# STM32MP21_CA35 register map
File version: 0.4
CPU: CM33 r0p1, little endian, MPU, FPU, vendor SysTick, 8 interrupt priority bits
Registers are 32-bit, read-write, reset 0x0 unless marked. A register's access mark holds for its fields unless they carry their own. Offsets are from the block's base; [hi:lo] are bit positions; lines under a group give offsets from that group; {n}, {i} and the like mark numbered series.

## I3C1 (part 2 of 2) — I3C register block
Base 0x40190000
Same registers: I3C2 0x401A0000, I3C3 0x46080000, I3C1_S 0x50190000, I3C2_S 0x501A0000, I3C3_S 0x56080000
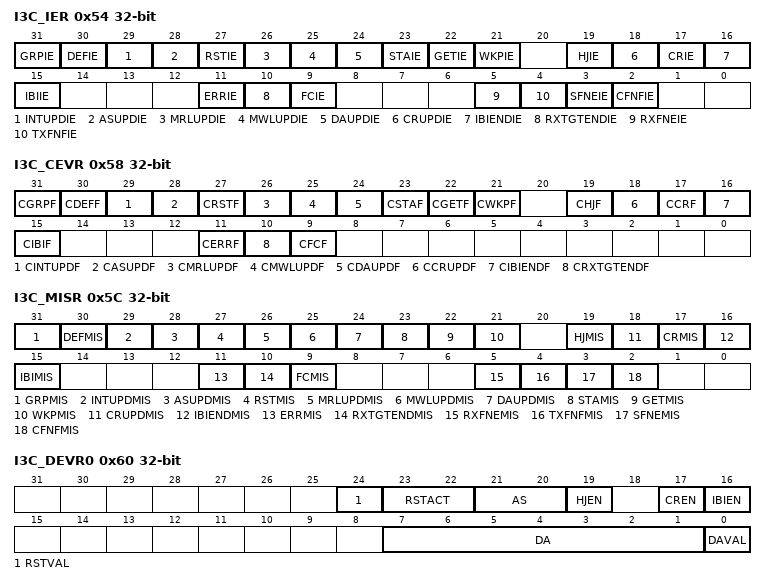
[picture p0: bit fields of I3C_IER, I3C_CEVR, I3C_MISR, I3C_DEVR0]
0x54 I3C_IER ro — I3C interrupt enable register
  [all] fields
    0=interrupt disabled; 1=interrupt enabled
  [31] GRPIE — DEFGRPA CCC interrupt enable (when the I3C acts as target)
  [30] DEFIE — DEFTGTS CCC interrupt enable (when the I3C acts as target)
  [29] INTUPDIE — ENEC/DISEC CCC interrupt enable (when the I3C acts as target)
  [28] ASUPDIE — ENTASx CCC interrupt enable (when the I3C acts as target)
  [27] RSTIE — reset pattern interrupt enable (when the I3C acts as target)
  [26] MRLUPDIE — SETMRL CCC interrupt enable (when the I3C acts as target)
  [25] MWLUPDIE — SETMWL CCC interrupt enable (when the I3C acts as target)
  [24] DAUPDIE — ENTDAA/RSTDAA/SETNEWDA CCC interrupt enable (when the I3C acts as target)
  [23] STAIE — format 1 GETSTATUS CCC interrupt enable (when the I3C acts as target)
  [22] GETIE — GETxxx CCC interrupt enable (except GETSTATUS of format 1) (when the I3C acts as target)
  [21] WKPIE — Wake-up interrupt enable (when the I3C acts as target)
  [19] HJIE — Hot-join interrupt enable (when the I3C acts as controller)
  [18] CRUPDIE — Controller-role update interrupt enable (when the I3C acts as target)
  [17] CRIE — Controller-role request interrupt enable (when the I3C acts as controller)
  [16] IBIENDIE — IBI end interrupt enable (when the I3C acts as target)
  [15] IBIIE — IBI request interrupt enable (when the I3C acts as controller)
  [11] ERRIE — error interrupt enable (whatever the I3C acts as controller/target)
  [10] RXTGTENDIE — target-initiated read end interrupt enable (when the I3C acts as controller)
  [9] FCIE — frame complete interrupt enable (whatever the I3C acts as controller/target)
  [5] RXFNEIE — RX-FIFO not empty interrupt enable (whatever the I3C acts as controller/target)
  [4] TXFNFIE — TX-FIFO not full interrupt enable (whatever the I3C acts as controller/target)
  [3] SFNEIE — S-FIFO not empty interrupt enable when the I3C acts as controller
  [2] CFNFIE — C-FIFO not full interrupt enable when the I3C acts as controller
0x58 I3C_CEVR wo — I3C clear event register
  [31] CGRPF — Clear DEFGRPA CCC flag (when the I3C acts as target)
    0=no effect; 1=clear GRPF
  [30] CDEFF — Clear DEFTGTS CCC flag (when the I3C acts as target)
    0=no effect; 1=clear DEFF
  [29] CINTUPDF — Clear ENEC/DISEC CCC flag (when the I3C acts as target)
    0=no effect; 1=clear CINTUPDF
  [28] CASUPDF — Clear ENTASx CCC flag (when the I3C acts as target)
    0=no effect; 1=clear ASUPDF
  [27] CRSTF — Clear reset pattern flag (when the I3C acts as target)
    0=no effect; 1=clear RSTF
  [26] CMRLUPDF — Clear SETMRL CCC flag (when the I3C acts as target)
    0=no effect; 1=clear MRLUPDF
  [25] CMWLUPDF — Clear SETMWL CCC flag (when the I3C acts as target)
    0=no effect; 1=clear MWLUPDF
  [24] CDAUPDF — Clear ENTDAA/RSTDAA/SETNEWDA CCC flag (when the I3C acts as target)
    0=no effect; 1=clear DAUPDF
  [23] CSTAF — Clear format 1 GETSTATUS CCC flag (when the I3C acts as target)
    0=no effect; 1=clear STAF
  [22] CGETF — Clear GETxxx CCC flag (except GETSTATUS of format 1) (when the I3C acts as target)
    0=no effect; 1=clear GETF
  [21] CWKPF — Clear wake-up flag (when the I3C acts as target)
    0=no effect; 1=clear WKPF
  [19] CHJF — Clear hot-join flag (when the I3C acts as controller)
    0=no effect; 1=clear HJF
  [18] CCRUPDF — Clear controller-role update flag (when the I3C acts as target)
    0=no effect; 1=clear CRUPDF
  [17] CCRF — Clear controller-role request flag (when the I3C acts as controller)
    0=no effect; 1=clear CRF
  [16] CIBIENDF — Clear IBI end flag (when the I3C acts as target)
    0=no effect; 1=clear IBIENDF
  [15] CIBIF — Clear IBI request flag (when the I3C acts as controller)
    0=no effect; 1=clear IBIF
  [11] CERRF — Clear error flag (whatever the I3C acts as controller/target)
    0=no effect; 1=clear ERRF
  [10] CRXTGTENDF — Clear target-initiated read end flag (when the I3C acts as controller)
    0=no effect; 1=clear RXTGTENDF
  [9] CFCF — Clear frame complete flag (whatever the I3C acts as controller/target)
    0=no effect; 1=clear FCF
0x5C I3C_MISR ro — I3C masked interrupt status register
  [31] GRPMIS — DEFGRPA CCC masked interrupt status (when the I3C acts as target)
  [30] DEFMIS — DEFTGTS CCC masked interrupt status (when the I3C acts as target)
  [29] INTUPDMIS — ENEC/DISEC CCC masked interrupt status (when the I3C acts as target)
  [28] ASUPDMIS — ENTASx CCC masked interrupt status (when the I3C acts as target)
  [27] RSTMIS — reset pattern masked interrupt status (when the I3C acts as target)
  [26] MRLUPDMIS — SETMRL CCC masked interrupt status (when the I3C acts as target)
  [25] MWLUPDMIS — SETMWL CCC masked interrupt status (when the I3C acts as target)
  [24] DAUPDMIS — ENTDAA/RSTDAA/SETNEWDA CCC masked interrupt status (when the I3C acts as target)
  [23] STAMIS — format 1 GETSTATUS CCC masked interrupt status (when the I3C acts as target)
  [22] GETMIS — GETxxx CCC masked interrupt status, except GETSTATUS of format 1 (when the I3C acts as target)
  [21] WKPMIS — Wake-up/missed start masked interrupt status (when the I3C acts as target)
  [19] HJMIS — Hot-join masked interrupt status (when the I3C acts as controller)
  [18] CRUPDMIS — Controller-role update masked interrupt status (when the I3C acts as target)
  [17] CRMIS — Controller-role request masked interrupt status (when the I3C acts as controller)
  [16] IBIENDMIS — IBI end masked interrupt status (when the I3C acts as target)
  [15] IBIMIS — IBI request masked interrupt status (when the I3C acts as controller)
  [11] ERRMIS — error masked interrupt status (whatever the I3C acts as controller/target)
  [10] RXTGTENDMIS — target-initiated read end masked interrupt status (when the I3C acts as controller)
  [9] FCMIS — frame complete masked interrupt status (whatever the I3C acts as controller/target)
  [5] RXFNEMIS — RX-FIFO not empty masked interrupt status (whatever the I3C acts as controller/target)
  [4] TXFNFMIS — TX-FIFO not full masked interrupt status (whatever the I3C acts as controller/target)
  [3] SFNEMIS — S-FIFO not empty masked interrupt status (when the I3C acts as controller)
  [2] CFNFMIS — C-FIFO not full masked interrupt status (when the I3C acts as controller)
0x60 I3C_DEVR0 — I3C own device characteristics register
  [24] RSTVAL ro — Reset action is valid (when the I3C acts as target) This bit is asserted by hardware to indicate that the RSTACT[1:0] field has been updated on the reception of a broadcast or direct write RSTACT CCC (target reset action) and is valid. This bit is cleared by hardware when the target receives a frame start. When the device is not in Stop mode: If RSTVAL = 1: when RSTF in the I3C_EVR register is asserted (and/or the corresponding interrupt if enabled), RSTACT[1:0] in the I3C_DEVR0 register dictates the reset action to be performed by the software, if any. If RSTVAL = 0: when RSTF is asserted (and/or the corresponding interrupt if enabled), the software must issue an I3C reset after a first detected reset pattern, and a system reset on the second one. When in Stop mode, the corresponding interrupt can be used to wake up the device.
  [23:22] RSTACT ro — Reset action/level on received reset pattern (when the I3C acts as target) This read field is used by hardware on the reception of a direct read RSTACT CCC in order to return the corresponding data byte on the I3C bus. This read field is updated by hardware on the reception of a broadcast or direct write RSTACT CCC (target reset action). Only the defining bytes 0x00, 0x01 and 0x02 are mapped, and RSTACT[1:0] = Defining Byte[1:0]. a) partially reset the peripheral, by a write and clear of the enable bit of the I3C configuration register (write EN = 0). This resets the I3C bus interface and the I3C kernel sub-parts, without modifying the content of the I3C APB registers (except the EN bit). b) fully reset the peripheral, including all its registers, via a write and set of the I3C reset control bit of the RCC (reset and clock controller) register. the software writes and sets the SYSRESETREQ control bit of the AITR register, when the device is controlled by a Cortexsup /sup-M. the software writes and sets SYSRST = 1 in the RCC_GRSTCSETR register, when the device is controlled by a Cortexsup /sup-A.
    0=no reset action; 1=first level of reset: the application software must either:; 2=second level of reset: the application software must issue a warm reset, also known as a system reset. This (see Section20: Reset and clock control (RCC)) has the same impact as a pin reset (NRST = 0):; 3=no reset action
  [21:20] AS ro — Activity state (when the I3C acts as target) This read field is updated by hardware on the reception of a ENTASx CCC (enter activity state, with x = 0-3):
    {v}=activity state {v} (v=0..3)
  [19] HJEN — Hot-join request enable (when the I3C acts as target) This bit is initially written by software when EN = 0, and is updated by hardware on the reception of DISEC CCC with DISHJ= 1 (cleared) and the reception of ENEC CCC with ENHJ= 1 (set). This bit can only be written by software when EN = 0 in the I3C_CFGR register.
    0=hot-join request disabled; 1=hot-join request enabled
  [17] CREN — Controller-role request enable (when the I3C acts as target) This bit is initially written by software when EN = 0, and is updated by hardware on the reception of DISEC CCC with DISCR = 1 (cleared) and the reception of ENEC CCC with ENCR=1 (set). This bit can only be written by software when EN = 0 in the I3C_CFGR register.
    0=controller-role request disabled; 1=controller-role request enabled
  [16] IBIEN — IBI request enable (when the I3C acts as target) This bit is initially written by software when EN = 0, and is updated by hardware on the reception of DISEC CCC with DISINT = 1 (cleared) and the reception of ENEC CCC with ENINT = 1 (set). This bit can only be written by software when EN = 0 in the I3C_CFGR register.
    0=IBI request disabled; 1=IBI request enabled
  [7:1] DA — 7-bit dynamic address When the I3C acts as controller, this field can be written by software, for defining its own dynamic address. When the I3C acts as target, this field is updated by hardware on the reception of either the broadcast ENTDAA CCC or the direct SETNEWDA CCC.
  [0] DAVAL — Dynamic address is valid (when the I3C acts as target) When the I3C acts as controller, this bit can be written by software, for validating its own dynamic address, for example before a controller-role hand-off. When the I3C acts as target, this bit is asserted by hardware on the acknowledge of the broadcast ENTDAA CCC or the direct SETNEWDA CCC, and this field is cleared by hardware on the acknowledge of the broadcast RSTDAA CCC.
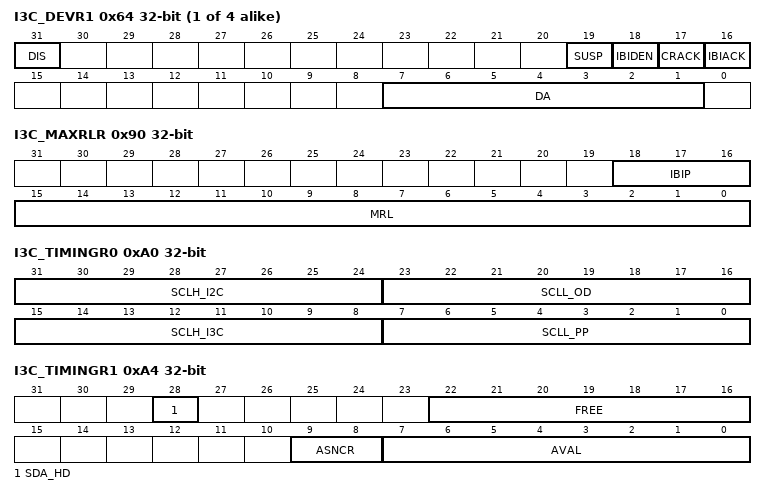
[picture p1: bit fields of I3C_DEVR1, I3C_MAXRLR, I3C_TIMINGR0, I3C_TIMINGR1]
{0x60+4i} I3C_DEVR{i} (i=1..4) — I3C device {i} characteristics register
  [31] DIS ro — DA[6:0] write disabled (when the I3C acts as controller) When the I3C acts as controller, once the software sets IBIACK= 1 or CRACK= 1, this read bit is set by hardware (DIS = 1) to lock the configured DA[6:0] and IBIDEN values. Then, to be able to modify DA[6:0], IBIDEN or SUSP, the software must wait for DIS to be de-asserted by hardware (polling on DIS = 0) before modifying these three assigned values to the target x. Indeed, the target can request an IBI or a controller-role while the controller intends to modify DA[6:0], IBIDEN or SUSP.
    0=write to DA[7:0] and to IBIDEN in the I3C_DEVRx register is allowed; 1=write to DA[7:0] and to IBIDEN is disabled/locked
  [19] SUSP — Suspend/stop I3C transfer on received IBI (when the I3C acts as controller) When the I3C acts as controller, this bit can be used to receive an IBI from target x with pending read notification feature (received MDB[7:5] = 3'b101). If this bit is set, when an IBI is received and completed (IBIF = 1 in the I3C_EVR register), a stop is emitted on the I3C bus and both C-FIFO and TX-FIFO are automatically flushed by hardware. The controller execution flow is stopped, even if a next control message is programmed. When the IBI is completed, the controller software can issue a new control word, such as a private read, to the target device that initiated the IBI request.
    0=C-FIFO and TX-FIFO are not flushed after an IBI request from target x is acknowledged and completed, and depending on the presence or absence of a next control word, a repeated start or a stop is emitted; 1=I3C transfer is stopped and both C-FIFO and TX-FIFO are flushed after receiving an IBI request from target x
  [18] IBIDEN — IBI data enable (when the I3C acts as controller) When the I3C acts as controller, this bit must be written by software to store the BCR[2] bit as received from the target x during broadcast ENTDAA or direct GETBCR CCC via the received I3C_RDR. Writing to this field has no impact when the DIS = 1 in the I3C_DEVRx register.
    0=no data byte follows the acknowledged IBI from target x; 1=the mandatory data byte MDB[7:0] follows the acknowledged IBI from target x
  [17] CRACK — Controller-role request acknowledge (when the I3C acts as controller) When the I3C acts as controller, this bit is written by software to define the acknowledge policy to be applied on the I3C bus on the reception of a controller-role request from target x: After the NACK, the message continues as initially programmed (the target is aware of the NACK and can emit another controller-role request later on) - The field DIS is asserted by hardware to protect DA[6:0] from being modified by software meanwhile the hardware can store internally the current DA[6:0] into the kernel clock domain. - After the ACK, the message continues as initially programmed. The software is notified by the controller-role request flag (CRF = 1 in the I3C_EVR register) and/or the corresponding interrupt if enabled; For effectively granting the controller-role to the requesting secondary controller, software must issue a GETACCCR (formerly known as GETACCMST), followed by a stop. - Independently of CRACK configuration for this or other devices, further controller-role request(s) are NACK-ed until controller-role request flag (CRF) and IBI flag (IBIF) in the I3C_EVR register are both cleared.
    0=a controller-role request from target x must be NACK-ed; 1=a controller-role request (with 7-bit dynamic address DA[6:0]) from target x must be ACKed
  [16] IBIACK — IBI request acknowledge (when the I3C acts as controller) When the I3C acts as controller, this bit is written by software to define the acknowledge policy to be applied on the I3C bus on the reception of an IBI request from target x: - After the NACK, the message continues as initially programmed (the target is aware of the NACK and can emit another IBI request later on) - The field DIS is asserted by hardware to protect DA[6:0] from being modified by software meanwhile the hardware can store internally the current DA[6:0] into the kernel clock domain. - After the ACK, the controller logs the IBI payload data, if any, depending on I3C_DEVRx.IBIDEN. - The software is notified by the IBI flag (IBIF = 1) and/or the corresponding interrupt if enabled; - Independently from IBIACK configuration for this or other devices, further IBI request(s) are NACK-ed until IBI request flag (IBIF) and controller-role request flag (CRF) are both cleared.
    0=an IBI request from target x must be NACK-ed; 1=an IBI request (with 7-bit dynamic address DA[6:0]) from target x must be ACKed
  [7:1] DA — Assigned I3C dynamic address to target x (when the I3C acts as controller) When the I3C acts as controller, this field must be written by software to store the 7-bit dynamic address that the controller sends via a broadcast ENTDAA or a direct SETNEWDA CCC acknowledged by the target x. Writing to this field has no impact when the read field DIS = 1 in the I3C_DEVRx register.
0x90 I3C_MAXRLR — I3C maximum read length register
  [18:16] IBIP — IBI payload data maximum size, in bytes (when I3C acts as target) This field is initially written by software when EN = 0 to set the maximum number of data bytes to be sent to the controller after an IBI request has been acknowledged.This field can be updated by hardware on the reception of SETMRL command (which potentially also updated IBIP[2:0]). Software is notified of an MRL update by MRLUPF in the I3C_EVR register and the corresponding interrupt, if enabled. others: same as 100
    0=null payload data size (only allowed when BCR2 = 0 in the I3C_BCR register); 1=1 byte (mandatory data byte MDB[7:0]; 2=2 bytes (including first MDB[7:0]); 3=3 bytes (including first MDB[7:0]); 4=4 bytes (including first MDB[7:0])
  [15:0] MRL — Maximum data read length (when I3C acts as target) This field is initially written by software when EN = 0 and updated by hardware on the reception of SETMRL command (with potentially also updated IBIP[2:0]). Software is notified of an MRL update by MRLUPF and the corresponding interrupt, if enabled. This field is used by hardware to return the value on the I3C bus when the target receives a GETMRL CCC.
0x94 I3C_MAXWLR — I3C maximum write length register
  [15:0] MWL — Maximum data write length (when I3C acts as target) This field is initially written by software when EN = 0 and updated by hardware on the reception of SETMWL command. Software is notified of an MWL update by MWLUPF in the I3C_EVR register and the corresponding interrupt, if enabled. This field is used by hardware to return the value on the I3C bus when the target receives a GETMWL CCC.
0xA0 I3C_TIMINGR0 — I3C timing register 0
  [31:24] SCLH_I2C — SCL high duration, used for legacy Isup2/supC messages, in number of kernel clocks cycles: tsubSCLH_I2C/sub=(SCLH_I2C+1)xtsubI3CCLK/sub Note: SCLH_I2C is used to generate tsubDIG_H /sub(Isup2/supC) timing when communicating with Isup2/supC devices. Note: With Isup2/supC fm+ device tsubDIG_Hmin/sub = 260 ns, with Isup2/supC fm device tsubDIG_Hmin/sub = 600 ns.
  [23:16] SCLL_OD — SCL low duration in open-drain phases, used for legacy Isup2/supC messages and for I3C open-drain phases (address phase following a start, ACK phase during controller-initiated messages, and T bit phase during direct/private/IBI payload), in number of kernel clocks cycles: tsubSCLL_OD/sub=(SCLL_OD+1)xtsubI3CCLK/sub Note: SCLL_OD is used to generate both tsubDIG_L /sub(Isup2/supC) and tsubDIG_OD_L/sub(I3C) timings. Note: With Isup2/supC fm+ device tsubDIG_Lmin/sub = 500 ns, with Isup2/supC fm device tsubDIG_Lmin/sub = 1320 ns. Note: I3C messages: tsubDIG_OD_Lmin /sub= 200 ns. Note: If a single I3C frame is gathering Isup2/supC and I3C messages, the SCL low duration during I3C open-drain phases is increased to fit Isup2/supC timings.
  [15:8] SCLH_I3C — SCL high duration, used for I3C messages (both in push-pull and open-drain phases), in number of kernel clocks cycles: tsubSCLH_I3C/sub=(SCLH_I3C+1)xtsubI3CCLK/sub Note: SCLH_I3C is used to generate both tsubDIG_H /sub(I3C) and tsubDIG_H_MIXED /subtimings. Note: For mixed bus (with at least one Isup2/supC target): tsubDIG_H_MIXEDmin /sub= 32 ns and tsubDIG_H_MIXEDmax /sub= 45 ns (due to Isup2/supC 50 ns spike filter). Note: For pure I3C bus (with no Isup2/supC targets): tsubDIG_Hmin/sub = 32 ns.
  [7:0] SCLL_PP — SCL low duration in I3C push-pull phases, in number of kernel clocks cycles: tsubSCLL_PP/sub=(SCLL_PP+1)xtsubI3CCLK/sub Note: SCLL_PP is used to generate tsubDIG_L/sub (I3C in PP) timing. Note: tsubDIG_Lmin/sub = 32 ns (max 40/60 duty cycle at 12.5 MHz).
0xA4 I3C_TIMINGR1 — I3C timing register 1
  [28] SDA_HD — SDA hold time (when the I3C acts as controller), in number of kernel clocks cycles (refer to MIPI timing SDA hold time in push-pull tsubHD_PP/sub): SDA hold time = (SDA_HD + 0.5) xtsubI3CCLK/sub Note: when controller: tsubHD_PPmiN =/sub min (tsubCR /sub, tsubCF/sub) + 3 ns.
  [22:16] FREE — Number of kernel clocks cycles that is used to set some MIPI timings like bus free condition time (when the I3C acts as controller) When the I3C acts as controller: for I3C start timing: it must wait for (bus free condition) time to be elapsed after a stop and before a start, refer to MIPI timings (I3C) tsubCAS /suband (Isup2/supC)sub /subtsubBUF/sub. These timings are defined by: tsubBUF/sub=tsubCAS/sub=[(FREE[6:0]+1)x2 - (0.5 + SDA_HD)] x tsubI3CCLK/sub Note: For pure I3C bus: tsubCASmin /sub=38.4 ns, and tsubCASmax/sub=1 s, 100 s, 2 ms, 50 ms for, respectively, ENTAS0, 1, 2, and 3. Note: For mixed bus with Isup2/supC fm+ device tsubBUFmin/sub = 0.5 s, for mixed bus with Isup2/supC fm device tsubBUFmin/sub = 1.3 s. for I3C repeated start timing: must wait for time to be elapsed after a repeated start (SDA is de-asserted) and before driving SCL low, refer to. MIPI timing tsubCASr/sub. This timing is defined by: tsubCASr/sub=[(FREE[6:0]+1)x2 - (0.5 + SDA_HD)] x tsubI3CCLK/sub. Note: tsubCASr, miN/sub=19.2 ns. for I3C stop timing: must wait for time to be elapsed after that the SCL clock is driven high, and before the stop condition (SDA is asserted). This timing is defined by: tsubCBP/sub=(FREE[6:0]+1) x tsubI3CCLK/sub. Note: tsubCBPmiN/sub=19.2 ns. for I3C repeated start timing (T-bit when controller ends read with repeated start followed by stop): must wait for time to be elapsed after that the SCL clock is driven high, and before the repeated start condition (SDA is de-asserted). This timing is defined by: tsubCBSr/sub=(FREE[6:0]+1) x tsubI3CCLK/sub. Note: tsubCBSr, miN/sub=19.2 ns.
  [9:8] ASNCR — Activity state of the new controller (when I3C acts as active controller) This field indicates the time to wait before being accessed as new target, refer AVAL[7:0]. This field can be modified only when the I3C acts as controller.
  [7:0] AVAL — Number of kernel clock cycles to set a time unit of 1 s, whatever I3C acts as controller or target. This time unit is then used by the hardware to build some internal timers, corresponding to the following MIPI I3C timings: When the I3C acts as target: for bus available condition time: it must wait for (bus available condition) time to be elapsed after a stop and before issuing a start request for an IBI or a controller-role request (bus free condition is sustained for at least tsubAVAL/sub). Refer to MIPI timing tsubAVAL/sub=1s. This timing is defined by: tsubAVAL/sub=(AVAL[7:0]+2)xtsubI3CCLK/sub for bus idle condition time: it must wait for (bus idle condition) time to be elapsed after that both SDA and SCL are continuously high and stable before issuing a hot-join event. Refer to MIPI v1.1 timing tsubIDLE/sub= 200 s . This timing is defined by: tsubIDLE/sub=(AVAL[7:0]+2)x200 x tsubI3CCLK/sub When the I3C acts as controller, it cannot stall the clock beyond a maximum stall time (stall the SCL clock low), as follows: on first bit of assigned address during dynamic address assignment: it cannot stall the clock beyond the MIPI timing tsubSTALLDAA/sub = 15 ms. This timing is defined by: tsubSTALLDAAmax/sub=(AVAL[7:0]+1)x15000 x tsubI3CCLK/sub on ACK/NACK phase of I3C/Isup2/supC transfer, on parity bit of write data transfer, on transition bit of I3C read transfer: it cannot stall the clock beyond the MIPI timing tsubSTALL/sub= 100 s. This timing is defined by: tsubSTALLmax/sub=(AVAL[7:0]+1)x100 x tsubI3CCLK/sub Whatever the I3C acts as controller or as (controller-capable) target, during a controller-role hand-off procedure: The new controller must wait for tsubNEWCRLock /subbefore pulling SDA low (issuing a start) after a completed GETACCR CCC. Then the new controller, within tsubCAS/sub, can pull SCL low to activate SCL clock. The active controller must wait for the same tsubNEWCRLock /subtime, or at least 100 s, before testing if the new controller has gained control of the bus by pulling SDA low. The time to wait depends upon the value of ANSCR[1:0] in the I3C_TIMINGR1 register: ASNCR[1:0] = 00: tsubNEWCRLock/sub=(AVAL[7:0]+1)x tsubI3CCLK/sub ASNCR[1:0] = 01: tsubNEWCRLock/sub=(AVAL[7:0]+1)x100 x tsubI3CCLK/sub ASNCR[1:0] = 10: tsubNEWCRLock/sub=(AVAL[7:0]+1)x2000 x tsubI3CCLK/sub ASNCR[1:0] = 11: tsubNEWCRLock/sub=(AVAL[7:0]+1)x50000 x tsubI3CCLK/sub
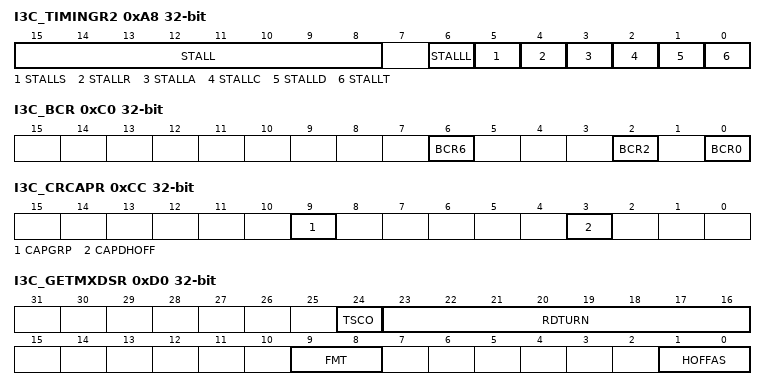
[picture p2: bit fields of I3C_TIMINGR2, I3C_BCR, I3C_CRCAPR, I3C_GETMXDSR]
0xA8 I3C_TIMINGR2 — I3C timing register 2
  [15:8] STALL — Controller clock stall time, in number of kernel clock cycles tsubSCLL_STALL/sub=STALL x tsubI3CCLK/sub
  [6] STALLL — Controller clock stall enable in the address ACK/NACK phase (before the ninth bit) of a legacy I2C read/write message.
    0=no stall; 1=stall enabled
  [5] STALLS — Controller clock stall enable in the data ACK/NACK phase of a legacy I2C write message.
    0=no stall; 1=stall enabled
  [4] STALLR — Controller clock stall enable in the data ACK/NACK phase of a legacy I2C read message.
    0=no stall; 1=stall enabled
  [3] STALLA — Controller clock stall enable on ACK phase The SCL is stalled (during tsubSCLL_STALL/subas defined by STALL) in the address ACK/NACK phase (before the ninth bit). This allows the target to prepare data. The ACK driven by the controller itself on a target-initiated request (IBI/HJ/CR) is not impacted by this control bit.
    0=no stall; 1=stall enabled
  [2] STALLC — Controller clock stall enable on PAR phase of CCC The SCL is stalled during STALLxtsubSCLL_PP /subin the T-bit phase of common command code (before the ninth bit). This allows the target to decode the command. Note: tsubSCLL_PP/sub=(I3C_TIMINGR0.SCLL_PP[7:0]+1)xtsubI3CCLK/sub
    0=no stall; 1=stall enabled
  [1] STALLD — Controller clock stall enable on PAR phase of Data The SCL is stalled during STALLxtsubSCLL_PP/sub in the T-bit phase (before the ninth bit). This allows the target to read received data. Note: tsubSCLL_PP/sub=(I3C_TIMINGR0.SCLL_PP[7:0]+1)xtsubI3CCLK/sub
    0=no stall; 1=stall enabled
  [0] STALLT — Controller clock stall enable on T-bit phase of data (and on the ACK/NACK phase of data byte of a legacy Isup2/supC read) The SCL is stalled during STALLxtsubSCLL_PP/sub in the T-bit phase (before the ninth bit). This allows the target to prepare the data to be sent. Note: tsubSCLL_PP/sub=(I3C_TIMINGR0.SCLL_PP[7:0]+1)xtsubI3CCLK/sub
    0=no stall; 1=stall enabled
0xC0 I3C_BCR — I3C bus characteristics register
  [6] BCR6 — Controller capable
    0=I3C target (no controller capable); 1=I3C controller capable
  [2] BCR2 — in-band interrupt (IBI) payload
    0=no data byte follows the accepted IBI; 1=at least one mandatory data byte follows the accepted IBI (and at most 4 data bytes)
  [0] BCR0 — max data speed limitation
    0=no limitation; 1=limitation, as described by I3C_GETMXDSR
0xC4 I3C_DCR — I3C device characteristics register
  [7:0] DCR — device characteristics ID others: ID to describe the type of the I3C sensor/device Note: The latest MIPI DCR ID assignments are available on https://www.mipi.org.
    0=generic device (for v1.0 devices)
0xC8 I3C_GETCAPR — I3C get capability register
  [14] CAPPEND — IBI MDB support for pending read notification This bit is written by software during bus initialization (EN = 0), and indicates the support (or not) of the pending read notification via the IBI MDB[7:0] value. This bit is used to return the GETCAP3 byte in response to the GETCAPS CCC format 1.
    0=this I3C when acting as target sends an IBI request without a mandatory data byte value indicating a pending read notification; 1=this I3C when acting as target sends an IBI request with a mandatory data byte value (MDB[7:5] = 101), indicating a pending read notification
0xCC I3C_CRCAPR — I3C controller-role capability register
  [9] CAPGRP — group management support (when acting as controller) This bit is written by software during bus initialization (EN = 0), and indicates if the I3C is able to support group management when it acts as a controller (after controller-role hand-off) via emitted DEFGRPA, RSTGRPA, and SETGRPA CCC. This bit is used to return the CRCAP1 byte in response to the GETCAPS CCC format 2.
    0=this I3C does not support group address capabilities; 1=this I3C supports group address capabilities (when becoming controller)
  [3] CAPDHOFF — delayed controller-role hand-off This bit is written by software during bus initialization (EN = 0), and indicates if this target I3C needs additional time to process a controller-role hand-off requested by the current controller. This bit is used to return the CRCAP2 byte in response to the GETCAPS CCC format 2.
    0=this I3C does not needs additional time to process a controller-role hand-off; 1=this I3C needs additional time to process a controller-role hand-off
0xD0 I3C_GETMXDSR — I3C get max data speed register
  [24] TSCO — clock-to-data turnaround time (tsubSCO/sub) This bit is written by software during bus initialization (EN = 0 in the I3C_CFGR register) and is used to specify the clock-to-data turnaround time tsubSCO/sub (vs. the value of 12 ns). This bit is used by the hardware in response to the GETMXDS CCC to return the encoded clock-to-data turnaround time via the returned MaxRd[5:3] bits.
    0=tsubSCO/sub less than or eqaul 12 ns; 1=tsubSCO/sub 12 ns (refer to the datasheet for more details)
  [23:16] RDTURN — programmed byte of the 3-byte MaxRdTurn (maximum read turnaround byte) This bit is written by software during bus initialization (EN = 0) and writes the value of the selected byte (via the FMT[1:0] field) of the 3-byte MaxRdTurn, which is returned in response to the GETMXDS CCC format 2 to encode the maximum read turnaround time.
  [9:8] FMT — GETMXDS CCC format This field is written by software during bus initialization (EN = 0) and indicates how is returned the GETMXDS format 1 (without MaxRdTurn) and format 2 (with MaxRdTurn). This field is used to return the 2-byte format 1 (MaxWr, MaxRd) or 5-byte format 2 (MaxWr, MaxRd, 3-byte MaxRdTurn) byte in response to the GETCAPS CCC. - 3-byte MaxRdTurn is returned with MSB = 0, middle byte = 0 and LSB = RDTURN[7:0]. - Max read turnaround time is less than 256 s. - 3-byte MaxRdTurn is returned with MSB = 0, middle byte = RDTURN[7:0] and LSB = 0. - Max read turnaround time is between 256 and 65535 s - 3-byte MaxRdTurn is returned with MSB = RDTURN[7:0], middle byte = 0 and LSB = 0. - Max read turnaround time is between 65535 s and 16 s.
    0=format 1 (2 bytes with MaxWr with no defining byte, MaxRd); 1=format 2: (5 bytes w.ith MaxWr with no defining byte, MaxRd, MaxRdTurn); 2=format 2 (5 bytes with MaxWr with no defining byte, MaxRd, and middle byte of MaxRdTurn); 3=format 2 (5 bytes with MaxWr with no defining byte, MaxRd, MSB of MaxRdTurn)
  [1:0] HOFFAS — Controller hand-off activity state This field is written by software during bus initialization (EN = 0), and indicates in which initial activity state the (other) current controller must expect the I3C bus after a controller-role hand-off to this controller-capable I3C, when returning the defining byte CRHDLY (0x91) to a GETMXDS CCC. This 2-bit field is used to return the CRHDLY1 byte in response to the GETCAPS CCC format 3, to state the activity state of this I3C when becoming controller after a controller-role hand-off, and consequently the time the former controller must wait before testing this I3C to be confirmed its ownership.
    0=activity state 0 is the initial activity state of this I3C before and when becoming controller; 1=activity state 1 is the initial activity state of this I3C when becoming controller; 2=activity state 2 is the initial activity state of this I3C when becoming controller; 3=activity state 3 is the initial activity state of this I3C when becoming controller
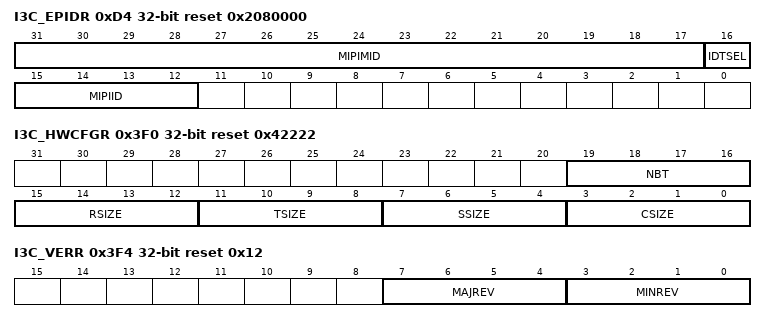
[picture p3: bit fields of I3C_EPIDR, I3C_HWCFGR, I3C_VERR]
0xD4 I3C_EPIDR reset 0x2080000 — I3C extended provisioned ID register
  [31:17] MIPIMID ro — 15-bit MIPI manufacturer ID This read field is the 15-bit STMicroelectronics MIPI ID (0x0104). This field represents bits[47:33] of the 48-bit provisioned ID.
  [16] IDTSEL ro — provisioned ID type selector This field is set as 0 (vendor fixed value). This field represents bit[32] of the 48-bit provisioned ID. Note: Bits[31:16] of the provisioned ID can be 0.
  [15:12] MIPIID — 4-bit MIPI Instance ID This field is written by software to set and identify individually each instance of this I3C IP with a specific number on a single I3C bus. This field represents bits[15:12] of the 48-bit provisioned ID. Note: Bits[11:0] of the provisioned ID can be 0.
0x3F0 I3C_HWCFGR ro reset 0x42222 — I3C hardware configuration register
  [19:16] NBT — number of targets whose the IBI/controller-role request can be managed in parallel by this I3C IP, when acting as controller This value drives the maximum value x of the I3C_DEVRx.
  [15:12] RSIZE — RX-FIFO size, in multiple of 4 bytes. Note: A RX-FIFO element is a (received) byte.
  [11:8] TSIZE — TX-FIFO size, in multiple of 4 bytes. Note: A TX-FIFO element is a (transmitted) byte.
  [7:4] SSIZE — S-FIFO size, in multiple of (32-bit) words. Note: A S-FIFO element is a (status) word.
  [3:0] CSIZE — C-FIFO size, in multiple of (32-bit) words. Note: A C-FIFO element is a (control) word.
0x3F4 I3C_VERR ro reset 0x12 — I3C version register
  [7:4] MAJREV — I3C major revision
  [3:0] MINREV — I3C minor revision
0x3F8 I3C_IPIDR ro reset 0x130081 — I3C identification register
  [31:0] ID — I3C identification
0x3FC I3C_SIDR ro reset 0xA3C5DD01 — I3C size identification register
  [31:0] SID — I3C address space size identification (1 Kbyte)
